AUTOSAR XML (schema 4-0-3)
standard types defined: Boolean, UInt32
package /AUTOSAR_Platform/DataConstrs
  range DC_Boolean: raw 0..1
package /PATAC/MSM/ComponentTypes
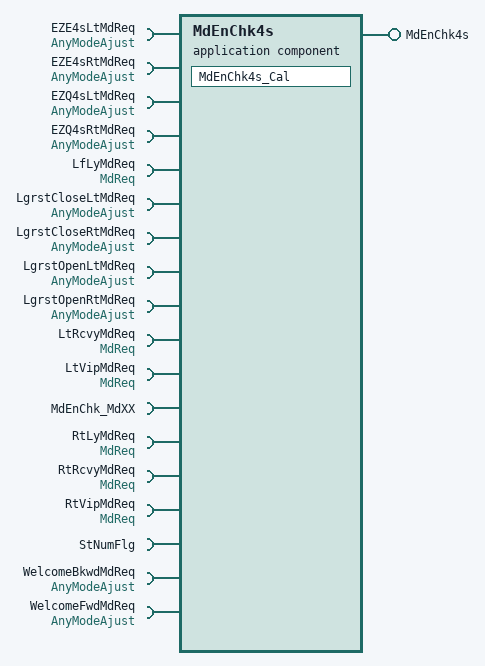
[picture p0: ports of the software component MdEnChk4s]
  application sw component type MdEnChk4s
    provide port MdEnChk4s: server-com-spec{operation=MdEnChk4s/Cal, queue-length=1}, provided-interface=MdEnChk4s
    18 x require port:
      EZE4sLtMdReq: nonqueued-receiver-com-spec{data-element=AnyModeAjust/Val, filter=data-filter-type=ALWAYS, init-value=0}, required-interface=AnyModeAjust
      EZE4sRtMdReq: nonqueued-receiver-com-spec{data-element=AnyModeAjust/Val, filter=data-filter-type=ALWAYS, init-value=0}, required-interface=AnyModeAjust
      EZQ4sLtMdReq: nonqueued-receiver-com-spec{data-element=AnyModeAjust/Val, filter=data-filter-type=ALWAYS, init-value=0}, required-interface=AnyModeAjust
      EZQ4sRtMdReq: nonqueued-receiver-com-spec{data-element=AnyModeAjust/Val, filter=data-filter-type=ALWAYS, init-value=0}, required-interface=AnyModeAjust
      LfLyMdReq: nonqueued-receiver-com-spec{data-element=MdReq/Val, filter=data-filter-type=ALWAYS, init-value=0}, required-interface=MdReq
      LgrstCloseLtMdReq: nonqueued-receiver-com-spec{data-element=AnyModeAjust/Val, filter=data-filter-type=ALWAYS, init-value=0}, required-interface=AnyModeAjust
      LgrstCloseRtMdReq: nonqueued-receiver-com-spec{data-element=AnyModeAjust/Val, filter=data-filter-type=ALWAYS, init-value=0}, required-interface=AnyModeAjust
      LgrstOpenLtMdReq: nonqueued-receiver-com-spec{data-element=AnyModeAjust/Val, filter=data-filter-type=ALWAYS, init-value=0}, required-interface=AnyModeAjust
      LgrstOpenRtMdReq: nonqueued-receiver-com-spec{data-element=AnyModeAjust/Val, filter=data-filter-type=ALWAYS, init-value=0}, required-interface=AnyModeAjust
      LtRcvyMdReq: nonqueued-receiver-com-spec{data-element=MdReq/Val, filter=data-filter-type=ALWAYS, init-value=0}, required-interface=MdReq
      LtVipMdReq: nonqueued-receiver-com-spec{data-element=MdReq/Val, filter=data-filter-type=ALWAYS, init-value=0}, required-interface=MdReq
      MdEnChk_MdXX: client-com-spec=MdEnChk_MdXX/Cal, required-interface=MdEnChk_MdXX
      RtLyMdReq: nonqueued-receiver-com-spec{data-element=MdReq/Val, filter=data-filter-type=ALWAYS, init-value=0}, required-interface=MdReq
      RtRcvyMdReq: nonqueued-receiver-com-spec{data-element=MdReq/Val, filter=data-filter-type=ALWAYS, init-value=0}, required-interface=MdReq
      RtVipMdReq: nonqueued-receiver-com-spec{data-element=MdReq/Val, filter=data-filter-type=ALWAYS, init-value=0}, required-interface=MdReq
      StNumFlg: required-interface=StNumFlg
        required-com-specs:
          data-element=Is4s, filter=data-filter-type=ALWAYS, init-value=0
          data-element=Is6s, filter=data-filter-type=ALWAYS, init-value=0
          data-element=Is6s7s, filter=data-filter-type=ALWAYS, init-value=0
          data-element=Is7s, filter=data-filter-type=ALWAYS, init-value=0
      WelcomeBkwdMdReq: nonqueued-receiver-com-spec{data-element=AnyModeAjust/Val, filter=data-filter-type=ALWAYS, init-value=0}, required-interface=AnyModeAjust
      WelcomeFwdMdReq: nonqueued-receiver-com-spec{data-element=AnyModeAjust/Val, filter=data-filter-type=ALWAYS, init-value=0}, required-interface=AnyModeAjust
    behavior MdEnChk4s_InternalBehavior
      operation invoked event OIT_MdEnChk4s_Cal_MdEnChk4s_Cal: start-on-event=MdEnChk4s_Cal, operation=MdEnChk4s.Cal
      runnable MdEnChk4s_Cal
        data-receive-point-by-arguments:
          20 x access:
            REC_EZE4sLtMdReq_Val: accessed-variable=EZE4sLtMdReq.Val
            REC_EZE4sRtMdReq_Val: accessed-variable=EZE4sRtMdReq.Val
            REC_EZQ4sLtMdReq_Val: accessed-variable=EZQ4sLtMdReq.Val
            REC_EZQ4sRtMdReq_Val: accessed-variable=EZQ4sRtMdReq.Val
            REC_LfLyMdReq_Val: accessed-variable=LfLyMdReq.Val
            REC_LgrstCloseLtMdReq_Val: accessed-variable=LgrstCloseLtMdReq.Val
            REC_LgrstCloseRtMdReq_Val: accessed-variable=LgrstCloseRtMdReq.Val
            REC_LgrstOpenLtMdReq_Val: accessed-variable=LgrstOpenLtMdReq.Val
            REC_LgrstOpenRtMdReq_Val: accessed-variable=LgrstOpenRtMdReq.Val
            REC_LtRcvyMdReq_Val: accessed-variable=LtRcvyMdReq.Val
            REC_LtVipMdReq_Val: accessed-variable=LtVipMdReq.Val
            REC_RtLyMdReq_Val: accessed-variable=RtLyMdReq.Val
            REC_RtRcvyMdReq_Val: accessed-variable=RtRcvyMdReq.Val
            REC_RtVipMdReq_Val: accessed-variable=RtVipMdReq.Val
            REC_StNumFlg_Is4s: accessed-variable=StNumFlg.Is4s
            REC_StNumFlg_Is6s: accessed-variable=StNumFlg.Is6s
            REC_StNumFlg_Is6s7s: accessed-variable=StNumFlg.Is6s7s
            REC_StNumFlg_Is7s: accessed-variable=StNumFlg.Is7s
            REC_WelcomeBkwdMdReq_Val: accessed-variable=WelcomeBkwdMdReq.Val
            REC_WelcomeFwdMdReq_Val: accessed-variable=WelcomeFwdMdReq.Val
        sync call SC_MdEnChk_MdXX_Cal: operation=MdEnChk_MdXX.Cal, timeout=0
  swc implementation MdEnChk4s_Implementation: behavior=MdEnChk4s_InternalBehavior
    code-descriptors:
      code Default: artifact-descriptors=autosar-engineering-object={short-label=Default, category=SWSRC}
package /PATAC/MSM/ModeAdjust/PortInterface
  client server interface MdEnChk_MdXX
    operation Cal  # StNun: 0 :4s 1:6s 2:7s 3:4sp
      5 x arg, all with direction=IN, server-argument-impl-policy=USE-ARGUMENT-TYPE:
        Req: type=DataTypes/Boolean
        ChkBsyBit: type=UInt32
        SetEnBit: type=UInt32
        SetBsyBit: type=UInt32
        MdAvl: type=DataTypes/Boolean
  client server interface MdEnChk4s
    operation Cal
  sender receiver interface AnyModeAjust: invalidation-policy{data-element=AnyModeAjust/Val, handle-invalid=DONT-INVALIDATE}
    data Val: type=Implementation/Boolean
  sender receiver interface MdReq: invalidation-policy{data-element=MdReq/Val, handle-invalid=DONT-INVALIDATE}
    data Val: type=Implementation/Boolean
  sender receiver interface StNumFlg
    4 x data, all with type=Implementation/Boolean:
      Is4s
      Is6s
      Is6s7s
      Is7s
    invalidation-policys:
      data-element=Is7s, handle-invalid=DONT-INVALIDATE
      data-element=Is6s, handle-invalid=DONT-INVALIDATE
      data-element=Is4s, handle-invalid=DONT-INVALIDATE
      data-element=Is6s7s, handle-invalid=DONT-INVALIDATE
